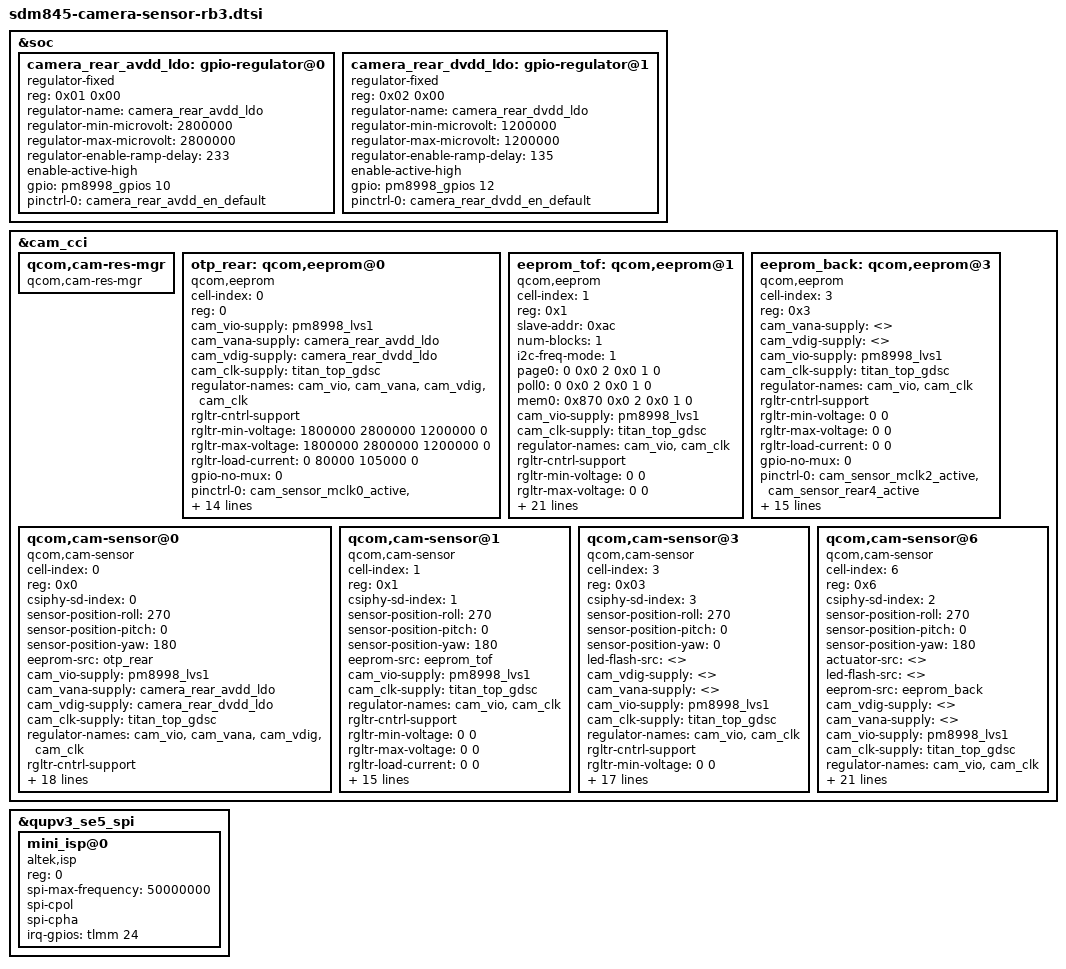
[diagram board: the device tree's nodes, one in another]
/*
 * Copyright (c) 2019, The Linux Foundation. All rights reserved.
 *
 * This program is free software; you can redistribute it and/or modify
 * it under the terms of the GNU General Public License version 2 and
 * only version 2 as published by the Free Software Foundation.
 *
 * This program is distributed in the hope that it will be useful,
 * but WITHOUT ANY WARRANTY; without even the implied warranty of
 * MERCHANTABILITY or FITNESS FOR A PARTICULAR PURPOSE.  See the
 * GNU General Public License for more details.
 */

&soc {
	camera_rear_avdd_ldo: gpio-regulator@0 {
		compatible = "regulator-fixed";
		reg = <0x01 0x00>;
		regulator-name = "camera_rear_avdd_ldo";
		regulator-min-microvolt = <2800000>;
		regulator-max-microvolt = <2800000>;
		regulator-enable-ramp-delay = <233>;
		enable-active-high;
		gpio = <&pm8998_gpios 10 0>;
		pinctrl-names = "default";
		pinctrl-0 = <&camera_rear_avdd_en_default>;
	};

	camera_rear_dvdd_ldo: gpio-regulator@1 {
		compatible = "regulator-fixed";
		reg = <0x02 0x00>;
		regulator-name = "camera_rear_dvdd_ldo";
		regulator-min-microvolt = <1200000>;
		regulator-max-microvolt = <1200000>;
		regulator-enable-ramp-delay = <135>;
		enable-active-high;
		gpio = <&pm8998_gpios 12 0>;
		pinctrl-names = "default";
		pinctrl-0 = <&camera_rear_dvdd_en_default>;
	};
};

&cam_cci {
	qcom,cam-res-mgr {
		compatible = "qcom,cam-res-mgr";
		status = "ok";
	};

	otp_rear: qcom,eeprom@0 {
		cell-index = <0>;
		reg = <0>;
		compatible = "qcom,eeprom";
		cam_vio-supply = <&pm8998_lvs1>;
		cam_vana-supply = <&camera_rear_avdd_ldo>;
		cam_vdig-supply = <&camera_rear_dvdd_ldo>;
		cam_clk-supply = <&titan_top_gdsc>;
		regulator-names = "cam_vio", "cam_vana", "cam_vdig",
			"cam_clk";
		rgltr-cntrl-support;
		rgltr-min-voltage = <1800000 2800000 1200000 0>;
		rgltr-max-voltage = <1800000 2800000 1200000 0>;
		rgltr-load-current = <0 80000 105000 0>;
		gpio-no-mux = <0>;
		pinctrl-names = "cam_default", "cam_suspend";
		pinctrl-0 = <&cam_sensor_mclk0_active
				&cam_sensor_rear_active>;
		pinctrl-1 = <&cam_sensor_mclk0_suspend
				&cam_sensor_rear_suspend>;
		gpios = <&tlmm 13 0>,
			<&tlmm 9 0>;
		gpio-reset = <1>;
		gpio-req-tbl-num = <0 1>;
		gpio-req-tbl-flags = <1 0>;
		gpio-req-tbl-label = "CAMIF_MCLK0",
					"CAM_RESET0";
		sensor-position = <0>;
		sensor-mode = <0>;
		cci-master = <0>;
		status = "ok";
		clocks = <&clock_camcc CAM_CC_MCLK0_CLK>;
		clock-names = "cam_clk";
		clock-cntl-level = "turbo";
		clock-rates = <24000000>;
	};

	eeprom_tof: qcom,eeprom@1 {
		cell-index = <1>;
		reg = <0x1>;
		compatible = "qcom,eeprom";
		slave-addr = <0xac>;
		num-blocks = <1>;
		i2c-freq-mode = <1>;

		page0 = <0 0x0 2 0x0 1 0>;
		poll0 = <0 0x0 2 0x0 1 0>;
		mem0 = <0x870 0x0 2 0x0 1 0>;

		cam_vio-supply = <&pm8998_lvs1>;
		cam_clk-supply = <&titan_top_gdsc>;
		regulator-names = "cam_vio", "cam_clk";
		rgltr-cntrl-support;
		rgltr-min-voltage = <0 0>;
		rgltr-max-voltage = <0 0>;
		rgltr-load-current = <0 0>;
		gpio-no-mux = <0>;
		pinctrl-names = "cam_default", "cam_suspend";
		pinctrl-0 = <&cam_sensor_mclk1_active
			&cam_sensor_tof_active>;
		pinctrl-1 = <&cam_sensor_mclk1_suspend
			&cam_sensor_tof_suspend>;
		gpios = <&tlmm 14 0>,
		      <&tlmm 8 0>;
		gpio-reset = <1>;
		gpio-req-tbl-num = <0 1>;
		gpio-req-tbl-flags = <1 0>;
		gpio-req-tbl-label = "CAMIF_MCLK1","CAM_RESET1";
		cci-master = <0>;

		qcom,cam-power-seq-type ="cam_reset","cam_vio",
			"cam_clk","cam_reset";
		qcom,cam-power-seq-val = "cam_reset","cam_vio",
			"cam_mclk","cam_reset";
		qcom,cam-power-seq-cfg-val = <0 1 24000000 1>;
		qcom,cam-power-seq-delay = <1 0 1 18>;

		status = "ok";
		clocks = <&clock_camcc CAM_CC_MCLK1_CLK>;
		clock-names = "cam_clk";
		clock-cntl-level = "turbo";
		clock-rates = <24000000>;
	};

	eeprom_back: qcom,eeprom@3 {
		cell-index = <3>;
		reg = <0x3>;
		compatible = "qcom,eeprom";
		cam_vana-supply = <>;
		cam_vdig-supply = <>;
		cam_vio-supply = <&pm8998_lvs1>;
		cam_clk-supply = <&titan_top_gdsc>;
		regulator-names = "cam_vio", "cam_clk";
		rgltr-cntrl-support;
		rgltr-min-voltage = <0 0>;
		rgltr-max-voltage = <0 0>;
		rgltr-load-current = <0 0>;
		gpio-no-mux = <0>;
		pinctrl-names = "cam_default", "cam_suspend";
		pinctrl-0 = <&cam_sensor_mclk2_active
				&cam_sensor_rear4_active>;
		pinctrl-1 = <&cam_sensor_mclk2_suspend
				&cam_sensor_rear4_suspend>;
		gpios = <&tlmm 15 0>,
			<&tlmm 12 0>,
			<&tlmm 69 0>;
		gpio-reset = <1>;
		gpio-custom1 = <2>;
		gpio-req-tbl-num = <0 1 2>;
		gpio-req-tbl-flags = <1 0 0>;
		gpio-req-tbl-label = "CAMIF_MCLK4",
					"CAM_RESET4",
					"CAM_CUSTOM4";
		sensor-position = <0>;
		sensor-mode = <0>;
		cci-master = <1>;
		status = "ok";
		clocks = <&clock_camcc CAM_CC_MCLK2_CLK>;
		clock-names = "cam_clk";
		clock-cntl-level = "turbo";
		clock-rates = <24000000>;
	};

	qcom,cam-sensor@0 {
		cell-index = <0>;
		compatible = "qcom,cam-sensor";
		reg = <0x0>;
		csiphy-sd-index = <0>;
		sensor-position-roll = <270>;
		sensor-position-pitch = <0>;
		sensor-position-yaw = <180>;
		eeprom-src = <&otp_rear>;
		cam_vio-supply = <&pm8998_lvs1>;
		cam_vana-supply = <&camera_rear_avdd_ldo>;
		cam_vdig-supply = <&camera_rear_dvdd_ldo>;
		cam_clk-supply = <&titan_top_gdsc>;
		regulator-names = "cam_vio", "cam_vana", "cam_vdig",
			"cam_clk";
		rgltr-cntrl-support;
		rgltr-min-voltage = <1800000 2800000 1200000 0>;
		rgltr-max-voltage = <1800000 2800000 1200000 0>;
		rgltr-load-current = <0 80000 105000 0>;
		gpio-no-mux = <0>;
		pinctrl-names = "cam_default", "cam_suspend";
		pinctrl-0 = <&cam_sensor_mclk0_active
				&cam_sensor_rear_active>;
		pinctrl-1 = <&cam_sensor_mclk0_suspend
				&cam_sensor_rear_suspend>;
		gpios = <&tlmm 13 0>,
			<&tlmm 9 0>;
		gpio-reset = <1>;
		gpio-req-tbl-num = <0 1>;
		gpio-req-tbl-flags = <1 0>;
		gpio-req-tbl-label = "CAMIF_MCLK0",
					"CAM_RESET0";
		sensor-mode = <0>;
		cci-master = <0>;
		status = "ok";
		clocks = <&clock_camcc CAM_CC_MCLK0_CLK>;
		clock-names = "cam_clk";
		clock-cntl-level = "turbo";
		clock-rates = <24000000>;
	};

	qcom,cam-sensor@1 {
		cell-index = <1>;
		compatible = "qcom,cam-sensor";
		reg = <0x1>;
		csiphy-sd-index = <1>;
		sensor-position-roll = <270>;
		sensor-position-pitch = <0>;
		sensor-position-yaw = <180>;
		eeprom-src = <&eeprom_tof>;
		cam_vio-supply = <&pm8998_lvs1>;
		cam_clk-supply = <&titan_top_gdsc>;
		regulator-names = "cam_vio", "cam_clk";
		rgltr-cntrl-support;
		rgltr-min-voltage = <0 0>;
		rgltr-max-voltage = <0 0>;
		rgltr-load-current = <0 0>;
		gpio-no-mux = <0>;
		pinctrl-names = "cam_default", "cam_suspend";
		pinctrl-0 = <&cam_sensor_mclk1_active
						&cam_sensor_tof_active>;
		pinctrl-1 = <&cam_sensor_mclk1_suspend
						&cam_sensor_tof_suspend>;
		gpios = <&tlmm 14 0>,
				<&tlmm 8 0>;
		gpio-reset = <1>;
		gpio-req-tbl-num = <0 1>;
		gpio-req-tbl-flags = <1 0>;
		gpio-req-tbl-label = "CAMIF_MCLK1","CAM_RESET1";
		sensor-mode = <0>;
		cci-master = <0>;
		status = "ok";
		clocks = <&clock_camcc CAM_CC_MCLK1_CLK>;
		clock-names = "cam_clk";
		clock-cntl-level = "turbo";
		clock-rates = <24000000>;
	};

	qcom,cam-sensor@3 {
		cell-index = <3>;
		compatible = "qcom,cam-sensor";
		reg = <0x03>;
		csiphy-sd-index = <3>;
		sensor-position-roll = <270>;
		sensor-position-pitch = <0>;
		sensor-position-yaw = <0>;
		led-flash-src = <>;
		cam_vdig-supply = <>;
		cam_vana-supply = <>;
		cam_vio-supply = <&pm8998_lvs1>;
		cam_clk-supply = <&titan_top_gdsc>;
		regulator-names = "cam_vio", "cam_clk";
		rgltr-cntrl-support;
		rgltr-min-voltage = <0 0>;
		rgltr-max-voltage = <0 0>;
		rgltr-load-current = <0 0>;
		gpio-no-mux = <0>;
		pinctrl-names = "cam_default", "cam_suspend";
		pinctrl-0 = <&cam_sensor_mclk3_active
				 &cam_sensor_tracking_active>;
		pinctrl-1 = <&cam_sensor_mclk3_suspend
				 &cam_sensor_tracking_suspend>;
		gpios = <&tlmm 16 0>,
			<&tlmm 21 0>;
		gpio-reset = <1>;
		gpio-req-tbl-num = <0 1>;
		gpio-req-tbl-flags = <1 0>;
		gpio-req-tbl-label = "CAMIF_MCLK3",
					"CAM_RESET3";
		sensor-mode = <0>;
		cci-master = <1>;
		status = "ok";
		clocks = <&clock_camcc CAM_CC_MCLK3_CLK>;
		clock-names = "cam_clk";
		clock-cntl-level = "turbo";
		clock-rates = <24000000>;
	};

	qcom,cam-sensor@6 {
		cell-index = <6>;
		compatible = "qcom,cam-sensor";
		reg = <0x6>;
		csiphy-sd-index = <2>;
		sensor-position-roll = <270>;
		sensor-position-pitch = <0>;
		sensor-position-yaw = <180>;
		actuator-src = <>;
		led-flash-src = <>;
		eeprom-src = <&eeprom_back>;
		cam_vdig-supply = <>;
		cam_vana-supply = <>;
		cam_vio-supply = <&pm8998_lvs1>;
		cam_clk-supply = <&titan_top_gdsc>;
		regulator-names = "cam_vio", "cam_clk";
		rgltr-cntrl-support;
		rgltr-min-voltage = <0 0>;
		rgltr-max-voltage = <0 0>;
		rgltr-load-current = <0 0>;
		gpio-no-mux = <0>;
		pinctrl-names = "cam_default", "cam_suspend";
		pinctrl-0 = <&cam_sensor_mclk2_active
				&cam_sensor_rear4_active>;
		pinctrl-1 = <&cam_sensor_mclk2_suspend
				&cam_sensor_rear4_suspend>;
		gpios = <&tlmm 15 0>,
			<&tlmm 12 0>,
			<&tlmm 69 0>;
		gpio-reset = <1>;
		gpio-custom1 = <2>;
		gpio-req-tbl-num = <0 1 2>;
		gpio-req-tbl-flags = <1 0 0>;
		gpio-req-tbl-label = "CAMIF_MCLK4",
					"CAM_RESET4",
					"CAM_CUSTOM4";
		sensor-mode = <0>;
		cci-master = <1>;
		status = "ok";
		clocks = <&clock_camcc CAM_CC_MCLK2_CLK>;
		clock-names = "cam_clk";
		clock-cntl-level = "turbo";
		clock-rates = <24000000>;
	};
};

&qupv3_se5_spi {
	status = "ok";
	mini_isp@0 {
		compatible = "altek,isp";
		reg = <0>;
		spi-max-frequency = <50000000>;
		spi-cpol;
		spi-cpha;
		/*spi-cs-high;*/
		irq-gpios = <&tlmm 24 0x00>;
		status = "ok";
	};
};
